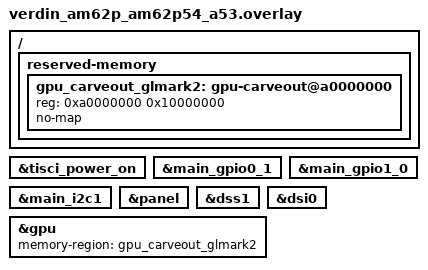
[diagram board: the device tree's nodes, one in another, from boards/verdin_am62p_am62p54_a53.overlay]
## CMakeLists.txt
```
# SPDX-License-Identifier: Apache-2.0
# SPDX-FileCopyrightText: 2026 Signal Slot, Inc.
# glmark2: glmark2-es2 (Linaro's OpenGL ES 2.0 benchmark) as a Zephyr image on
# the board layer, one source for the Verdin AM62P, the Verdin iMX8M Plus and
# the Raspberry Pi 4 (driver/docs/glmark2.md).
#
#   -DGLMARK2_SRC=<glmark2 checkout at GLMARK2_COMMIT>
#
# glmark2 is GPL-3.0-or-later (its libmatrix is MIT). It is never vendored or
# committed here: its sources are compiled by path from the fetched tree. The
# one file this port changes, libmatrix/util.cc (MIT), is copied into the
# build directory and patched there (patches/). Everything else of upstream
# is compiled unchanged, including CanvasGeneric, GLStateEGL, the glad
# loaders and the bundled libpng / zlib / libjpeg-turbo. Ours: the native
# state over the board layer and the run (src/main.cpp), the dlopen/dlsym
# shim over eglGetProcAddress and the data-file lookup (src/platform.c).
cmake_minimum_required(VERSION 3.20.0)

get_filename_component(PVR_REPO "${CMAKE_CURRENT_SOURCE_DIR}/../../.." ABSOLUTE)
include("${CMAKE_CURRENT_SOURCE_DIR}/../common/yakogl_dir.cmake")

# The STM32MP257F-DK's A35 takes the board layer's own app.conf (the Vivante
# driver, OP-TEE's watchdog, no hold), as gl_test, gc_fence and gc_clear do;
# boards/stm32mp257f_dk_stm32mp257fxx_a35.conf and .overlay add glmark2's own
# needs. Zephyr merges EXTRA_CONF_FILE after the board's .conf, so app.conf
# (HOLD_S=0) wins over prj.conf's.
if(NOT BOARD AND DEFINED ENV{BOARD})
  set(BOARD "$ENV{BOARD}")
endif()
if(BOARD MATCHES "^stm32mp257f_dk")
  set(EXTRA_CONF_FILE "${PVR_REPO}/zephyr/lib/board/stm32mp2/app.conf" ${EXTRA_CONF_FILE})
endif()

find_package(Zephyr REQUIRED HINTS $ENV{ZEPHYR_BASE})
project(glmark2_zephyr)

# ---------------------------------------------------------------------------
# The upstream tree, at the pinned commit and unmodified.
# ---------------------------------------------------------------------------
set(GLMARK2_COMMIT 22c527cb0556f3a1ac4445aaa52cc532760928d5)
set(GLMARK2_VERSION "2023.01") # meson.build project version at that commit
if(NOT GLMARK2_SRC AND DEFINED ENV{GLMARK2_SRC})
  set(GLMARK2_SRC "$ENV{GLMARK2_SRC}")
endif()
if(NOT GLMARK2_SRC OR NOT EXISTS "${GLMARK2_SRC}/src/default-benchmarks.h")
  message(FATAL_ERROR
    "glmark2: GLMARK2_SRC='${GLMARK2_SRC}' is not a glmark2 checkout. Fetch it:\n"
    "  git clone https://github.com/glmark2/glmark2 <dir> && git -C <dir> checkout ${GLMARK2_COMMIT}\n"
    "and pass -DGLMARK2_SRC=<dir>.")
endif()
execute_process(COMMAND git -C "${GLMARK2_SRC}" rev-parse HEAD
  OUTPUT_VARIABLE _gm_head OUTPUT_STRIP_TRAILING_WHITESPACE
  ERROR_QUIET RESULT_VARIABLE _gm_rc)
if(NOT _gm_rc EQUAL 0)
  set(_gm_head "unknown")
endif()
execute_process(COMMAND git -C "${GLMARK2_SRC}" status --porcelain --untracked-files=no
  OUTPUT_VARIABLE _gm_dirty OUTPUT_STRIP_TRAILING_WHITESPACE ERROR_QUIET)
if(NOT _gm_head STREQUAL GLMARK2_COMMIT OR NOT _gm_dirty STREQUAL "")
  # A score names the code that produced it: another commit, or a modified
  # tree, is not the pinned glmark2.
  message(FATAL_ERROR
    "glmark2: ${GLMARK2_SRC} is at '${_gm_head}' (local changes: '${_gm_dirty}'), "
    "not the pinned ${GLMARK2_COMMIT} without local changes.")
endif()
set(GM "${GLMARK2_SRC}/src")
set(GM_DATA "${GLMARK2_SRC}/data")
set(GM_BUILD "${CMAKE_CURRENT_BINARY_DIR}/glmark2")
message(STATUS "glmark2: upstream ${GLMARK2_COMMIT} (${GLMARK2_VERSION}) from ${GLMARK2_SRC}")

include("${CMAKE_CURRENT_SOURCE_DIR}/../common/sample.cmake")

# ---------------------------------------------------------------------------
# libmatrix/util.cc: copied and patched (Zephyr: the data files come from the
# image, the way upstream's ANDROID arm takes them from the APK's assets).
# ---------------------------------------------------------------------------
set(_util_patch "${CMAKE_CURRENT_SOURCE_DIR}/patches/libmatrix-util-zephyr.patch")
set(_util_cc "${GM_BUILD}/src/libmatrix/util.cc")
find_program(PATCH patch REQUIRED)
add_custom_command(OUTPUT "${_util_cc}"
  COMMAND ${CMAKE_COMMAND} -E make_directory "${GM_BUILD}/src/libmatrix"
  COMMAND ${CMAKE_COMMAND} -E copy "${GM}/libmatrix/util.cc" "${_util_cc}"
  COMMAND ${PATCH} --batch --forward -p1 -d "${GM_BUILD}" -i "${_util_patch}"
  DEPENDS "${GM}/libmatrix/util.cc" "${_util_patch}"
  COMMENT "glmark2: patching libmatrix/util.cc for Zephyr")

# ---------------------------------------------------------------------------
# The data files (data/shaders, data/models, data/textures), linked in as
# they are and decoded on the board by upstream's own readers. One .S with an
# .incbin per file and a table of {name, data, size}; the names are the paths
# glmark2 asks for under GLMARK_DATA_PATH ("/glmark2").
# ---------------------------------------------------------------------------
file(GLOB_RECURSE _gm_data_files RELATIVE "${GM_DATA}" CONFIGURE_DEPENDS
     "${GM_DATA}/shaders/*" "${GM_DATA}/models/*" "${GM_DATA}/textures/*")
list(SORT _gm_data_files)
set(_asm "/* generated by glmark2/CMakeLists.txt: the glmark2 data files */\n")
string(APPEND _asm "\t.section .rodata.glmark2_data, \"a\"\n")
set(_names "\t.section .rodata.glmark2_names, \"a\"\n")
set(_tab "\t.section .rodata.glmark2_table, \"a\"\n\t.balign 8\n")
string(APPEND _tab "\t.global glmark2_asset_table\nglmark2_asset_table:\n")
set(_i 0)
set(_bytes 0)
set(_deps)
foreach(f ${_gm_data_files})
  file(SIZE "${GM_DATA}/${f}" _sz)
  math(EXPR _bytes "${_bytes} + ${_sz}")
  list(APPEND _deps "${GM_DATA}/${f}")
  string(APPEND _asm "\t.balign 16\n.Ld${_i}:\n\t.incbin \"${GM_DATA}/${f}\"\n.Ld${_i}_end:\n")
  string(APPEND _names ".Ln${_i}:\n\t.asciz \"/glmark2/${f}\"\n")
  string(APPEND _tab "\t.quad .Ln${_i}, .Ld${_i}, .Ld${_i}_end - .Ld${_i}\n")
  math(EXPR _i "${_i} + 1")
endforeach()
string(APPEND _tab "\t.global glmark2_asset_table_count\n\t.balign 8\n")
string(APPEND _tab "glmark2_asset_table_count:\n\t.quad ${_i}\n")
set(_assets_s "${CMAKE_CURRENT_BINARY_DIR}/glmark2_assets.S")
file(CONFIGURE OUTPUT "${_assets_s}" CONTENT "${_asm}${_names}${_tab}")
set_source_files_properties("${_assets_s}" PROPERTIES OBJECT_DEPENDS "${_deps}")
message(STATUS "glmark2: ${_i} data files, ${_bytes} bytes linked in")

# ---------------------------------------------------------------------------
# Upstream's sources: src/meson.build's common_sources, the GLESv2 glad
# loader and the EGL state (the glmark2-es2 flavours), unchanged.
# ---------------------------------------------------------------------------
set(_gm_cxx
  benchmark-collection.cpp benchmark.cpp canvas-generic.cpp gl-headers.cpp
  gl-visual-config.cpp image-reader.cpp
  libmatrix/log.cc libmatrix/mat.cc libmatrix/program.cc libmatrix/shader-source.cc
  main-loop.cpp mesh.cpp model.cpp options.cpp results-file.cpp
  scene-buffer.cpp scene-build.cpp scene-bump.cpp scene-clear.cpp scene-conditionals.cpp
  scene.cpp scene-default-options.cpp scene-desktop.cpp scene-effect-2d.cpp
  scene-function.cpp scene-grid.cpp
  scene-ideas/a.cc scene-ideas.cpp scene-ideas/d.cc scene-ideas/e.cc scene-ideas/i.cc
  scene-ideas/lamp.cc scene-ideas/logo.cc scene-ideas/m.cc scene-ideas/n.cc
  scene-ideas/o.cc scene-ideas/s.cc scene-ideas/splines.cc scene-ideas/table.cc
  scene-ideas/t.cc
  scene-jellyfish.cpp scene-loop.cpp scene-pulsar.cpp scene-refract.cpp
  scene-shading.cpp scene-shadow.cpp
  scene-terrain/base-renderer.cpp scene-terrain/blur-renderer.cpp
  scene-terrain/copy-renderer.cpp scene-terrain.cpp scene-terrain/luminance-renderer.cpp
  scene-terrain/normal-from-height-renderer.cpp scene-terrain/overlay-renderer.cpp
  scene-terrain/renderer-chain.cpp scene-terrain/simplex-noise-renderer.cpp
  scene-terrain/terrain-renderer.cpp scene-terrain/texture-renderer.cpp
  scene-texture.cpp shared-library.cpp text-renderer.cpp texture.cpp
  gl-state-egl.cpp)
list(TRANSFORM _gm_cxx PREPEND "${GM}/")
set(_gm_glad "${GM}/glad/src/gles2.c" "${GM}/glad/src/egl.c")

# The bundled image libraries (src/{zlib,libpng,libjpeg-turbo}/meson.build).
set(_zlib adler32.c compress.c crc32.c deflate.c gzclose.c gzlib.c gzread.c gzwrite.c
  infback.c inffast.c inflate.c inftrees.c trees.c uncompr.c zutil.c)
list(TRANSFORM _zlib PREPEND "${GM}/zlib/")
set(_png png.c pngerror.c pnggccrd.c pngget.c pngmem.c pngpread.c pngread.c pngrio.c
  pngrtran.c pngrutil.c pngset.c pngtrans.c pngvcrd.c pngwio.c pngwrite.c pngwtran.c
  pngwutil.c)
list(TRANSFORM _png PREPEND "${GM}/libpng/")
set(_jpeg jcapimin.c jcapistd.c jccoefct.c jccolor.c jcdctmgr.c jchuff.c jcinit.c
  jcmainct.c jcmarker.c jcmaster.c jcomapi.c jcparam.c jcphuff.c jcprepct.c jcsample.c
  jdapimin.c jdapistd.c jdatadst.c jdatasrc.c jdcoefct.c jdcolor.c jddctmgr.c jdhuff.c
  jdinput.c jdmainct.c jdmarker.c jdmaster.c jdmerge.c jdphuff.c jdpostct.c jdsample.c
  jerror.c jfdctflt.c jfdctfst.c jfdctint.c jidctflt.c jidctfst.c jidctint.c jidctred.c
  jmemmgr.c jmemnobs.c jquant1.c jquant2.c jsimd_none.c jutils.c)
list(TRANSFORM _jpeg PREPEND "${GM}/libjpeg-turbo/")

# Upstream's code is built in static libraries of its own, with upstream's
# warnings (-w: not our warning set), and with the kernel's flags and headers
# through zephyr_interface: Zephyr's way for libraries of an application
# (zephyr_library() is for modules). The app links them; the linker pulls in
# what main.cpp references (SceneCollection registers every scene).
foreach(lib zlib png jpeg)
  add_library(glmark2_${lib} STATIC ${_${lib}})
  target_include_directories(glmark2_${lib} PRIVATE
    "${GM}/zlib" "${GM}/libpng" "${GM}/libjpeg-turbo")
  target_compile_options(glmark2_${lib} PRIVATE -w)
  target_link_libraries(glmark2_${lib} PUBLIC zephyr_interface)
  # kernel.h includes generated headers (heap_constants.h, ...)
  add_dependencies(glmark2_${lib} zephyr_generated_headers)
endforeach()
# zlib's gz* file functions use read/write/lseek/close: zlib's own configure
# defines Z_HAVE_UNISTD_H on a POSIX system.
target_compile_definitions(glmark2_zlib PRIVATE Z_HAVE_UNISTD_H)
target_compile_definitions(glmark2_png PRIVATE Z_HAVE_UNISTD_H)

add_library(glmark2_upstream STATIC ${_gm_cxx} ${_gm_glad} "${_util_cc}")
# YakoGL's include/ first: glad's EGL header takes <EGL/eglplatform.h> and
# <KHR/khrplatform.h> from there, so EGLNativeWindowType is YakoGL's
# struct gles_native_window * (glad's own eglplatform.h has no Zephyr arm).
# include/ holds the getopt.h, unistd.h and dlfcn.h glmark2 expects of a
# POSIX system (each says why).
target_include_directories(glmark2_upstream BEFORE PRIVATE
  "${YAKOGL_DIR}/include"
  "${GM}/glad/include" "${GM}" "${GM}/libmatrix" "${GM}/scene-ideas" "${GM}/scene-terrain"
  "${GM}/libpng" "${GM}/zlib" "${GM}/libjpeg-turbo"
  "${CMAKE_CURRENT_SOURCE_DIR}/include")
# _GNU_SOURCE: what g++ predefines on Linux, where glmark2 is built. Zephyr's
# POSIX layer sets _POSIX_C_SOURCE=200809L, which alone hides picolibc's XSI
# and BSD names (M_PI, used by the scenes).
target_compile_definitions(glmark2_upstream PRIVATE _GNU_SOURCE
  GLMARK2_USE_GLESv2 GLMARK2_USE_EGL USE_EXCEPTIONS
  GLMARK_VERSION="${GLMARK2_VERSION}" GLMARK_DATA_PATH="/glmark2"
  GLMARK2_EXECUTABLE="glmark2-es2")
target_compile_options(glmark2_upstream PRIVATE -w)
target_link_libraries(glmark2_upstream PUBLIC zephyr_interface
  glmark2_png glmark2_jpeg glmark2_zlib)
add_dependencies(glmark2_upstream zephyr_generated_headers)

# ---------------------------------------------------------------------------
# Ours.
# ---------------------------------------------------------------------------
target_sources(app PRIVATE src/main.cpp src/platform.c "${_assets_s}")
target_include_directories(app BEFORE PRIVATE
  "${YAKOGL_DIR}/include" "${CMAKE_CURRENT_SOURCE_DIR}/include"
  "${GM}/glad/include" "${GM}" "${GM}/libmatrix")
# The V3D OSAL's job times (zephyr_v3d.h), for the frame-cost line.
target_include_directories(app PRIVATE "${YAKOGL_DIR}/src/osal")
# The PowerVR backend's options (pvr_backend.h), for
# CONFIG_GLMARK2_PVR_ONE_KICK_IN_FLIGHT.
target_include_directories(app PRIVATE "${YAKOGL_DIR}/src/pvr")
target_compile_definitions(app PRIVATE
  GLMARK2_USE_GLESv2 GLMARK2_USE_EGL USE_EXCEPTIONS
  GLMARK2_COMMIT="${GLMARK2_COMMIT}" GLMARK_VERSION="${GLMARK2_VERSION}")
target_link_libraries(app PRIVATE glmark2_upstream)
```

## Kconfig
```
# SPDX-License-Identifier: Apache-2.0
# SPDX-FileCopyrightText: 2026 Signal Slot, Inc.
# What the glmark2 image runs (driver/docs/glmark2.md).

menu "glmark2"

config GLMARK2_SIZE
	string "Window size, WxH"
	default "800x600"
	help
	  The size of the board window, handed to glmark2 as --size. 800x600
	  is glmark2's own default (options.cpp:37) and the size of most
	  published glmark2-es2 runs on these boards; it fits all three panels
	  (1024x600, 1280x800, 1920x720). A window larger than the board can
	  give is refused by board_window() at the start of the run.

config GLMARK2_ARGS
	string "More glmark2 arguments, separated by spaces"
	default ""
	help
	  Appended after --size, e.g. "--off-screen" or
	  "-b build:use-vbo=true -b texture". Empty: the default benchmark
	  list (default-benchmarks.h, 33 scenes of 10 s each). --size and
	  --fullscreen here are refused (the window is sized from
	  GLMARK2_SIZE); --results-file needs a file system and is refused.

config GLMARK2_PVR_ONE_KICK_IN_FLIGHT
	bool "PowerVR: one kick in flight (measurement)"
	depends on YAKOGL_DRV_GPU_PVR
	help
	  Sets the PowerVR backend's PVR_BACKEND_OPT_ONE_IN_FLIGHT before the
	  first scene: each swap waits for its own frame's kick, not only for
	  the ones before it, so every kick starts on an idle GPU. With
	  CONFIG_YAKOGL_DRV_GPU_PVR_KICK_TIMES the kick line then shows the alone
	  cost of a frame's kick
	  (docs/notes/pvr-fence-wait.md, "The next
	  experiment"). A measurement knob: off for a score.

config GLMARK2_GC_TILED_RT
	bool "GC7000: tiled render targets and early depth (measurement)"
	depends on YAKOGL_DRV_GPU_VIVANTE
	select YAKOGL_TEST_KNOBS
	help
	  Calls gc_debug_set_tiled_rt(1) before the first scene: the Vivante
	  backend's tiled shadow targets, resolved by the RS in the same stream,
	  and early depth into them (docs/notes/gc-tiled-wire.md). The knob
	  exists only with CONFIG_YAKOGL_TEST_KNOBS, which this selects.
	  A measurement knob: off for a score.

config GLMARK2_FRAME_DUMP
	bool "Print each scene's last frame as text on the console"
	help
	  After a scene's last frame is read back for the picture value, prints
	  the whole window as "glmark2-fb:" lines (one base64 RGB888 row per
	  line, with the row number and a crc16, then a crc32 of the frame):
	  800x600 is about 1.9 MB, minutes of UART. tools/cts/glmark2-fb.py
	  turns the console log into a PNG (driver/docs/glmark2.md, "The frame
	  dump"). For a picture of one scene (GLMARK2_ARGS names it); off in every
	  gate and common-set image.

endmenu

source "Kconfig.zephyr"
```

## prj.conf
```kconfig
# SPDX-License-Identifier: Apache-2.0
# SPDX-FileCopyrightText: 2026 Signal Slot, Inc.
# The glmark2 image: the same configuration on every board. What a board
# needs beyond it (its GPU driver, display path, memory) is in boards/.
CONFIG_YAKOGL=y
CONFIG_YAKOGL_BOARD=y
# glmark2 builds its shaders at run time (options substituted into the
# sources): the in-process compiler.
CONFIG_YAKOGL_SHADERC_ONLINE=y

CONFIG_PRINTK=y
CONFIG_LOG=y
CONFIG_LOG_MODE_MINIMAL=y
CONFIG_CACHE_MANAGEMENT=y
CONFIG_FPU=y

# glmark2 is C++17 with exceptions (-DUSE_EXCEPTIONS), std::map/std::string
# everywhere, std::filesystem::path and iostreams: the full libstdc++, as
# dEQP has (deqp/prj.conf, deqp/README.md).
CONFIG_CPP=y
CONFIG_STD_CPP17=y
CONFIG_REQUIRES_FULL_LIBCPP=y
CONFIG_CPP_EXCEPTIONS=y
CONFIG_CPP_RTTI=y
# The SDK's libstdc++.a is built with a 64-bit `long` int64_t
# (deqp/README.md, "Configuration that matters").
CONFIG_ENFORCE_ZEPHYR_STDINT=n
# getopt_long for Options::parse_args; std::chrono::steady_clock for the
# frame times (clock_gettime).
CONFIG_POSIX_API=y
CONFIG_POSIX_C_LIB_EXT=y
CONFIG_GETOPT_LONG=y

# The online compiler needs 256 KiB of stack (examples/triangle/prj.conf); the
# scenes' model loaders recurse little. dEQP's 1 MiB, measured enough there.
CONFIG_MAIN_STACK_SIZE=1048576
CONFIG_STACK_SENTINEL=y
# The heap: decoded textures (largest 1024x1024x3, 3 MiB, plus libpng's row
# buffers), the parsed models (bunny.obj 2.4 MB of text) and the meshes.
# 96 MiB; the high-water mark is not measured yet.
CONFIG_COMMON_LIBC_MALLOC=y
CONFIG_COMMON_LIBC_MALLOC_ARENA_SIZE=100663296

# The run: 33 scenes of 10 s plus their set-up (shader compiles at about
# 0.2 s each on the A53, deqp/README.md) is about 6-7 minutes; the
# watchdog is fed until 15 minutes after boot at most, and every main-loop
# step says it is alive (NativeStateBoard::should_quit).
CONFIG_YAKOGL_BOARD_LIFETIME_S=900
CONFIG_YAKOGL_BOARD_HOLD_S=20
```

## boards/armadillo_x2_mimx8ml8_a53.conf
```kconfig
# SPDX-License-Identifier: Apache-2.0
# SPDX-FileCopyrightText: 2026 Signal Slot, Inc.
# Armadillo-X2 (i.MX8M Plus, same SoC and GC7000UL as the Verdin): what the
# board needs beyond prj.conf. The image is kexec'd out of Armadillo Base OS
# by tools/board.sh x2 run (kexec-dev, a development run); the record is read
# from SNVS LPGPR1..3 (three words).
#
# Build, one scene (CONFIG_GLMARK2_ARGS="-b terrain" selects it; any
# "-b <scene>" works, empty runs the default list):
#
#   export $(tools/cts/deps-env.sh imx8mp)
#   . "$ZEPHYR_VENV/bin/activate"
#   export ZEPHYR_BASE=$ZEPHYR_WS/zephyr
#   west build -p always -d <dir> -b armadillo_x2/mimx8ml8/a53 \
#       driver/samples/zephyr/glmark2 -- \
#       "-DZEPHYR_MODULES=$(tools/cts/zephyr-modules.sh $ZEPHYR_WS)" \
#       -DGLMARK2_SRC=$GLMARK2_SRC '-DCONFIG_GLMARK2_ARGS="-b terrain"'
#
# Check it; the run itself is a board session, not part of the build:
#   strings <dir>/zephyr/zephyr.bin | grep 'gc_wdog_arm: armed'
#   tools/board.sh --dry-run x2 run <dir>/zephyr/zephyr.bin <logdir>
CONFIG_YAKOGL_DRV_GPU_VIVANTE=y
CONFIG_YAKOGL_GPU_VIVANTE=y
# Board support of the GC images: the GIC EOI fix, the interrupt guard, the
# watchdog, the SNVS result record (gl_test's boards/imx8mp.conf has the same).
CONFIG_YAKOGL_GC_BOARD=y
# FPU sharing off on purpose, as the Verdin's.
CONFIG_FPU_SHARING=n
# The console is UART2, wired to the host: print there, not into the picture.
CONFIG_UART_CONSOLE=y
CONFIG_GC_COMMON_PANEL_CONSOLE=n
# tools/board.sh x2 refuses an image that does not print "gc_wdog_arm: armed".
CONFIG_GC_BOARD_WDOG_SELF_ARM=y
CONFIG_GPIO=y
CONFIG_I2C=y
CONFIG_PINCTRL=y
CONFIG_YAKOGL_DRV_DISPLAY_IMX8MP=y
CONFIG_PM_CPU_OPS=y
CONFIG_PM_CPU_OPS_PSCI=y
# Address space for the 240 MiB GPU carve-out of the overlay: the image with
# its 96 MiB heap plus that mapping is past the default 256 MiB of VM from
# 0x60000000 (the Verdin's conf has the same line, issue #814).
CONFIG_KERNEL_VM_SIZE=0x20000000
```

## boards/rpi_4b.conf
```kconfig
# SPDX-License-Identifier: Apache-2.0
# SPDX-FileCopyrightText: 2026 Signal Slot, Inc.
# Raspberry Pi 4: what the board needs beyond prj.conf, as slint/boards has
# it. Not built yet (driver/docs/glmark2.md).
CONFIG_YAKOGL_GPU_V3D=y
# 96 MiB of GPU memory (a static of the image; see rpi_4b.overlay): refract
# peaks at about 56.2 MB (its 1600x1200 copy, 7,684,096 B, did not fit the
# former 48 MiB: tools/cts/RESULTS.md, "out of GPU memory") and terrain needs
# over 30.5 MB, +33% since its 800x600 textures have NPOT mip chains. The
# carve-out and the 512 KiB page table sit inside the GPU's 512 MiB VA space
# (src/osal/zephyr_v3d.c, VA_SPACE), so 96 MiB has room.
CONFIG_YAKOGL_V3D_CARVEOUT_BYTES=100663296
# glmark2 refract's 1600x1200 RGBA8 colour render target tiles to 11,001,856 B
# with its mip chain: over the 8 MiB default, so one of its draws was refused
# (3 x GL error 0x505). Measured on the host harness at this carve-out: 24 MiB
# keeps that copy and the 7,684,096 B depth copy at once (tiled high-water
# 19,742,720 B; refract peak 69,093,376 of the 96 MiB carve-out, below the
# 70,146,048 of 16 MiB, which evicts the depth copy every frame; both run
# refract at 23 FPS):
# tools/hostharness/glmark2/FINDINGS-refract-budget.md sections 3.2-3.4.
CONFIG_YAKOGL_V3D_TILED_COPIES_BYTES=25165824
# The texture formatting unit: a colour render target the scene samples is
# stored by the tile list into its render image, and its glGenerateMipmap
# (refract's and terrain's, every frame) is one TFU job in that image instead
# of the CPU's box filter over 7.68 MB of non-cacheable storage
# (docs/online-shaderc/v3d-backend.md, "Render targets sampled from their
# render image"); the OSAL runs TFU jobs only with this option. Kept copies
# of 64 KiB or more are the TFU's too (case 140: 2.2 ms against 145 ms for a
# 1920x720 image). The first board run of the TFU's mipmap job is this
# image's.
CONFIG_YAKOGL_V3D_TFU=y
CONFIG_FPU_SHARING=y
# Address space: the image's 288 MiB (rpi_4b.overlay), the carve-out's
# non-cacheable alias (96 MiB), the window's alias, the framebuffer and the
# device blocks: more than slint's 256 MiB. deqp's pair, which runs on
# this board with a 256 MiB image (deqp/boards/rpi_4b.conf).
# The alias is 4 KiB pages, a table per 2 MiB: 48 for it, so 192 tables.
CONFIG_MAX_XLAT_TABLES=192
CONFIG_KERNEL_VM_SIZE=0x20000000
```

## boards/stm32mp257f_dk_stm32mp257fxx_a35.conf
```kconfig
# SPDX-License-Identifier: Apache-2.0
# SPDX-FileCopyrightText: 2026 Signal Slot, Inc.
# STM32MP257F-DK, Cortex-A35 (Vivante GCNanoUltra31, 0x8000/0x6205): what the
# board needs beyond prj.conf. The board layer's app.conf (the Vivante driver,
# OP-TEE's watchdog, no hold) is added by CMakeLists.txt, as in gl_test
# (boards/stm32mp257f_dk_stm32mp257fxx_a35.conf there, commit fb94dafe). Build
# only for now: the DK's board layer has no window or screen yet
# (board_stm32mp2.c: board_window() refuses), so the image links but a run
# ends at the first scene; the display is the DK's P8.
CONFIG_YAKOGL_BOARD=y
# The layer resets the board this long after boot whatever the run does: the
# default list is 33 scenes of 10 s plus set-up (prj.conf: about 6-7 minutes);
# tools/board-stm32mp2.sh's RUN_BOUND (120 s) has to be raised for it.
CONFIG_YAKOGL_STM32MP2_LIFETIME_S=900
# Address space for the 240 MiB GPU carve-out of the overlay: the image with
# its 96 MiB heap plus that mapping (gc_render.c, k_mem_map_phys_bare) is past
# the default 256 MiB of VM from 0xa0000000 (the Verdin iMX8M Plus' conf has
# the same line, issue #814).
CONFIG_KERNEL_VM_SIZE=0x20000000
```

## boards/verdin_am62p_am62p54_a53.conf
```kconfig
# SPDX-License-Identifier: Apache-2.0
# SPDX-FileCopyrightText: 2026 Signal Slot, Inc.
# Verdin AM62P: what the board needs beyond prj.conf, as slint/boards has it.
CONFIG_YAKOGL_DRV_GPU_PVR=y
CONFIG_FPU_SHARING=y
# A window up to 1920x1080 (8100 KiB), for an off-screen run at the size of
# the --fullscreen runs; the default 800x600 needs 1875.
CONFIG_YAKOGL_BOARD_WINDOW_MAX_KB=8100

# Init order: mailbox 40 -> TISCI 45 -> TISCI power-on 46 -> GPIO 47 ->
# I2C 50 -> DSI 70 -> DSS 80 -> GPU 90 -> panel bridge 95.
CONFIG_MBOX=y
CONFIG_MBOX_TI_SECURE_PROXY=y
CONFIG_TISCI=y
CONFIG_TISCI_INIT_PRIORITY=45
CONFIG_GPIO_INIT_PRIORITY=47
CONFIG_YAKOGL_DRV_SN65DSI8X_SELF_START_INIT_PRIORITY=95

# Address space for the 256 MiB GPU carve-out of the overlay (as the dEQP
# image has it): at the default the carve-out's mapping fails at boot
# ("insufficient virtual address space").
CONFIG_MAX_XLAT_TABLES=128
CONFIG_KERNEL_VM_SIZE=0x20000000
```

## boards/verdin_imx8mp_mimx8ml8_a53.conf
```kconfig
# SPDX-License-Identifier: Apache-2.0
# SPDX-FileCopyrightText: 2026 Signal Slot, Inc.
# Verdin iMX8M Plus (Mallow): what the board needs beyond prj.conf, as
# slint/boards has it. Not built yet (driver/docs/glmark2.md).
CONFIG_YAKOGL_DRV_GPU_VIVANTE=y
CONFIG_YAKOGL_GPU_VIVANTE=y
# FPU sharing off on purpose (slint/boards/verdin_imx8mp_mimx8ml8_a53.conf).
CONFIG_FPU_SHARING=n
# No UART on the Mallow: the console is the board layer's panel console.
CONFIG_UART_CONSOLE=n
CONFIG_GPIO=y
CONFIG_I2C=y
CONFIG_PINCTRL=y
CONFIG_YAKOGL_DRV_DISPLAY_IMX8MP=y
CONFIG_PM_CPU_OPS=y
CONFIG_PM_CPU_OPS_PSCI=y
# Address space for the 240 MiB GPU carve-out of the overlay:
# the image with its 96 MiB heap plus that mapping (gc_render.c,
# k_mem_map_phys_bare) is past the default 256 MiB of VM from 0x60000000,
# where the mapping fails at boot; 512 MiB, as the dEQP image of this board
# and the AM62P's glmark2 image have it.
CONFIG_KERNEL_VM_SIZE=0x20000000
```

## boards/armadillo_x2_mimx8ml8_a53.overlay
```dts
/* SPDX-License-Identifier: Apache-2.0 */
/* SPDX-FileCopyrightText: 2026 Signal Slot, Inc. */
/*
 * Armadillo-X2 (board definition: driver/boards/atmark/armadillo_x2). Two
 * changes for glmark2, neither in the board's own files.
 *
 * GPU carve-out: 240 MiB instead of the board's 128 MiB, as the Verdin's
 * glmark2 overlay has (issue #814: every GC7000 allocation of all the scenes
 * of a run comes from this one pool, and a refused allocation is a GL error).
 * It stays inside the 256 MiB at 0x80000000 that the board's map gives
 * galcore (gcContMem, no-map for Linux), ends at 0x8f000000 below Linux's
 * 0x90000000, and is 4 MiB aligned below 4 GiB as the GC's MMU needs. 240 MiB
 * is 60 of the 64 slave tables (gc_internal.h GC_STLB_COUNT). The image itself
 * stays in a53_ddr_section, 256 MiB at 0x60000000, the window tools/board.sh
 * x2 checks.
 *
 * Display: the board's devicetree expects the 1920x1200 that Linux ran on the
 * monitor; the HDMI sink now is a 1920x1080 capture device, and the adopt
 * driver refuses a LCDIF that runs another mode ("the LCDIF runs 1920x1080,
 * the devicetree expects 1920x1200"). It adopts the running mode and only
 * checks it against these two properties, so they say what runs.
 */
&gpu_carveout {
	reg = <0x80000000 0x0f000000>;
};

&display0 {
	hactive = <1920>;
	vactive = <1080>;
};
```

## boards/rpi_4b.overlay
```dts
/* SPDX-License-Identifier: Apache-2.0 */
/* SPDX-FileCopyrightText: 2026 Signal Slot, Inc. */
/*
 * The board's sram0 is 512 KiB at 0x200000 (dts/arm64/broadcom/bcm2711.dtsi).
 * This image carries the V3D's 96 MiB carve-out, the compiler's 2 MiB
 * scratch, the 96 MiB C heap (prj.conf), the window and glmark2's ~9.4 MB
 * of data files, so it gets 288 MiB from 0x200000, to 0x12200000 (an
 * estimate: the 224 MiB image of the 48 MiB carve-out took 194,192 KiB,
 * driver/docs/glmark2.md; +48 MiB is about 242 MiB). DRAM starts at 0 on the
 * Pi 4 and the firmware keeps its own memory at the top of the first GiB (the
 * framebuffer is at 0x3c100000), so this is ARM memory on every Pi 4.
 */
#include "../../common/rpi_4b_sram.dtsi"

&sram0 {
	reg = <0x200000 0x12000000>;
};
```

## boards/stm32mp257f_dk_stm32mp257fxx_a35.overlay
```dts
/* SPDX-License-Identifier: Apache-2.0 */
/* SPDX-FileCopyrightText: 2026 Signal Slot, Inc. */
/* The STM32MP257F-DK's A35: the board layer's GPU node (clock rate), as
 * gl_test, gc_fence and gc_clear take it, and a larger carve-out than the
 * board's. */
#include "../../../../zephyr/lib/board/stm32mp2/app.overlay"

/* A 240 MiB GPU carve-out instead of the board's 64 MiB gpu-reserved area at
 * 0xfa800000 (driver/boards/st/stm32mp257f_dk), as the Verdin iMX8M Plus'
 * glmark2 image takes (issue #814): every GC allocation of the scenes comes
 * from this one pool, frees are held until their kick completes, and one
 * scene's peak (terrain) is 51 MB on the host, more than 64 MiB holds with
 * the scenes running one after another. ST's area cannot grow: System RAM
 * ends at 0xfa7fffff, and U-Boot relocates just below that.
 *
 * Where: 0xb0000000, just above the image's 256 MiB (zephyr,sram at
 * 0xa0000000, the link address) and far below U-Boot, which relocates to the
 * top of usable RAM. It is System RAM in ST's Linux (0x84000000-0xfa7fffff),
 * not a reserved area, so unlike gpu-reserved it is not known to be open to
 * the GPU's bus master: the first run on the DK confirms it (gc_fence's
 * carve-out check). Below 4 GiB and 4 MiB aligned, as the GC's MMU needs
 * (mmu.rs); 240 MiB is 60 of the 64 slave tables the carve-out's head holds
 * (gc_internal.h GC_STLB_COUNT). */
/ {
	reserved-memory {
		gpu_carveout_glmark2: gpu-carveout@b0000000 {
			reg = <0xb0000000 0x0f000000>;
			no-map;
		};
	};
};

&gpu {
	memory-region = <&gpu_carveout_glmark2>;
};
```

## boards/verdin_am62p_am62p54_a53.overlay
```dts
/* SPDX-License-Identifier: Apache-2.0 */
/* SPDX-FileCopyrightText: 2026 Signal Slot, Inc. */
/*
 * Toradex Verdin AM62P (board definition). The board DTS has the GPU
 * node with its 64 MiB carveout and the display path wired but disabled
 * (the R5F owns the display in the platform). This stand-alone
 * application drives the panel itself, so it enables DSS1, DSI, the bridge
 * on I2C1, the GPIO banks and the TISCI power-on list.
 */

&tisci_power_on {
	status = "okay";
};

&main_gpio0_1 {
	status = "okay";
};

&main_gpio1_0 {
	status = "okay";
};

&main_i2c1 {
	status = "okay";
};

&panel {
	status = "okay";
};

&dss1 {
	status = "okay";
};

&dsi0 {
	status = "okay";
};

/* A 256 MiB GPU carve-out instead of the board's 64 MiB one, as the dEQP
 * image takes (driver/samples/zephyr/deqp/boards/, run from U-Boot on
 * 2026-10-12 with 0 resets). At 64 MiB about 36 MiB are taken whatever the
 * scene (firmware, parameter buffer, freelists, HWRT sets;
 * docs/notes/pvr-render-pool.md), so terrain's 5.6 MB
 * NPOT mip chain and shadow's 22 MB depth chain cannot fit and refract's
 * target allocations are refused. The board's 64 MiB region
 * stays reserved but unused. */
/ {
	reserved-memory {
		gpu_carveout_glmark2: gpu-carveout@a0000000 {
			reg = <0xa0000000 0x10000000>;
			no-map;
		};
	};
};

&gpu {
	memory-region = <&gpu_carveout_glmark2>;
};
```

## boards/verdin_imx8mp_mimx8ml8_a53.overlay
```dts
/* SPDX-License-Identifier: Apache-2.0 */
/* SPDX-FileCopyrightText: 2026 Signal Slot, Inc. */
/* The display chain of the Verdin iMX8M Plus on a Mallow carrier. */
#include "../../common/verdin_imx8mp_display.dtsi"

/* A 240 MiB GPU carve-out instead of the board's 64 MiB one.
 * Every GC7000 allocation comes from this one pool (src/osal/zephyr_gc.c),
 * and so do the board layer's 800x600 window and its 1280x800 screen copy
 * (5.7 MiB). At 64 MiB the GC's own peak in terrain is 51 MB on the host
 * (tools/hostharness/glmark2, one scene per process, frees returned at
 * once); on the board the frees are held until their kick completes and the
 * scenes run one after another in one pool, and a refused allocation is a
 * GL error (the record's "GL errors raised 15 or more" on every common set).
 * The AM62P's image took the same step for the same scenes (its overlay,
 * 256 MiB: 2573 GL errors to 0).
 *
 * Where: 0x70000000, above the image's 256 MiB at 0x60000000 and below the
 * M7's reserved 0x80000000 (the board's Linux /proc/iomem: System RAM from
 * 0x55500000 to 0x7fffffff; nothing runs from it while this image does).
 * Below 4 GiB and 4 MiB-aligned, as the GC's MMU needs (mmu.rs: the
 * carve-out is identity-mapped, one slave table per 4 MiB).
 * How much: 240 MiB, 60 of the 64 slave tables the carve-out's head holds
 * (gc_internal.h GC_STLB_COUNT, 256 MiB of VA); the other four are for
 * gc_render_map_phys's imports. tools/hostharness/glmark2/run.sh reads this
 * node, so the host run models the same memory. */
/ {
	reserved-memory {
		gpu_carveout_glmark2: gpu-carveout@70000000 {
			reg = <0x70000000 0x0f000000>;
			no-map;
		};
	};
};

&gpu3d {
	memory-region = <&gpu_carveout_glmark2>;
};
```

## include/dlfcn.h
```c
/* SPDX-License-Identifier: Apache-2.0 */
/* SPDX-FileCopyrightText: 2026 Signal Slot, Inc. */
/*
 * dlfcn.h for the glmark2 image: glmark2's SharedLibrary (shared-library.cpp)
 * opens libEGL / libGLESv2 with dlopen and takes every entry point with
 * dlsym. In the image YakoGL is linked in, so "opening" a library always
 * succeeds and dlsym is eglGetProcAddress, which answers for every EGL and GL
 * entry point YakoGL has (src/gl/egl.rs, the PROCS table). src/platform.c.
 */
#ifndef GLMARK2_DLFCN_H
#define GLMARK2_DLFCN_H

#ifdef __cplusplus
extern "C" {
#endif

#define RTLD_LAZY     0x0001
#define RTLD_NOW      0x0002
#define RTLD_GLOBAL   0x0100
#define RTLD_LOCAL    0x0000
#define RTLD_NODELETE 0x1000

void *dlopen(const char *filename, int flags);
void *dlsym(void *handle, const char *symbol);
int dlclose(void *handle);
char *dlerror(void);

#ifdef __cplusplus
}
#endif

#endif /* GLMARK2_DLFCN_H */
```

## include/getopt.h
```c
/* SPDX-License-Identifier: Apache-2.0 */
/* SPDX-FileCopyrightText: 2026 Signal Slot, Inc. */
/*
 * getopt.h for glmark2's options.cpp: Zephyr's getopt.h
 * (subsys/portability/posix/c_lib_ext/getopt) declares getopt_long but not
 * optarg/optind, which POSIX puts in <unistd.h> and glibc's getopt.h also
 * declares. options.cpp includes only <getopt.h>, as on glibc.
 */
#ifndef GLMARK2_GETOPT_H
#define GLMARK2_GETOPT_H

#include_next <getopt.h>
#include <unistd.h>

#endif /* GLMARK2_GETOPT_H */
```

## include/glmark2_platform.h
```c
/* SPDX-License-Identifier: Apache-2.0 */
/* SPDX-FileCopyrightText: 2026 Signal Slot, Inc. */
/*
 * glmark2_platform.h -- what glmark2's patched libmatrix/util.cc
 * (patches/libmatrix-util-zephyr.patch) asks of the image: the data files
 * linked in by CMakeLists.txt (glmark2_assets.S) and the CPU count.
 * Implemented in src/platform.c.
 */
#ifndef GLMARK2_PLATFORM_H
#define GLMARK2_PLATFORM_H

#include <stddef.h>

#ifdef __cplusplus
extern "C" {
#endif

/* The data file at `path` (e.g. "/glmark2/textures/crate-base.png"):
 * 0 and *data, *size; -1 when the image holds no such file. */
int glmark2_asset_find(const char *path, const void **data, size_t *size);

/* The number of linked-in files, and the path of file i (< count). */
size_t glmark2_asset_count(void);
const char *glmark2_asset_name(size_t i);

/* The CPUs Zephyr runs on (arch_num_cpus()). */
unsigned int glmark2_num_cpus(void);

#ifdef __cplusplus
}
#endif

#endif /* GLMARK2_PLATFORM_H */
```

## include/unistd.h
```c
/* SPDX-License-Identifier: Apache-2.0 */
/* SPDX-FileCopyrightText: 2026 Signal Slot, Inc. */
/*
 * unistd.h for glmark2: Zephyr's <unistd.h> plus isatty(), which Zephyr does
 * not have with picolibc (only lib/libc/newlib/libc-hooks.c defines one).
 * glmark2's libmatrix/log.cc asks isatty(fileno(stdout)) to decide whether to
 * colour its lines; src/platform.c answers "not a terminal" (the console is a
 * UART log, read by tools, not a terminal).
 */
#ifndef GLMARK2_UNISTD_H
#define GLMARK2_UNISTD_H

#include_next <unistd.h>

#ifdef __cplusplus
extern "C" {
#endif

int isatty(int fd);

#ifdef __cplusplus
}
#endif

#endif /* GLMARK2_UNISTD_H */
```

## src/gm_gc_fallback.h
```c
/* SPDX-License-Identifier: Apache-2.0 */
/* SPDX-FileCopyrightText: 2026 Signal Slot, Inc. */
/*
 * gm_gc_fallback.h: the GC7000 back end's fallback and wait counters, the
 * source of PERF page 4 (gm_perf_page.h). The library provides the strong
 * definition of yakogl_gc_fallback_stats (item fb-counters); the sample
 * defines a __weak one returning -ENOTSUP, so an image built before the
 * library counters exist reports "not available" (page 4 = 0xffff in every
 * value) and cannot be mistaken for zero.
 *
 * The contract: every field is a cumulative count since boot, never reset,
 * 64 bits wide (no wrap to handle). The page takes the difference between
 * the scene's first frame and the end of its last.
 */
#ifndef GM_GC_FALLBACK_H
#define GM_GC_FALLBACK_H

#include <stdint.h>

#ifdef __cplusplus
extern "C" {
#endif

struct yakogl_gc_fallback_stats {
	/* glGenerateMipmap chains the GPU drew (once per call, however many
	 * levels the chain has) */
	uint64_t gpu_mip_chains;
	/* glGenerateMipmap calls that took the CPU filter instead */
	uint64_t cpu_mip_calls;
	/* times the CPU waited for the GPU outside the swap (the depth
	 * resolve's finish(), a tiled copy of a rendered texture, a readback
	 * of a render target; the swap's own wait is page 1) */
	uint64_t gpu_waits;
	/* bytes the CPU read or wrote in passes over the GPU carve-out
	 * (non-cacheable memory: tiled copies, CPU mipmaps, depth resolves) */
	uint64_t carveout_cpu_bytes;
};

/* Fills *out. 0 on success; -ENOTSUP when this build keeps no such counters
 * (the sample's weak definition); another negative errno on failure, which
 * the page treats like -ENOTSUP. */
int yakogl_gc_fallback_stats(struct yakogl_gc_fallback_stats *out);

#ifdef __cplusplus
}
#endif

#endif /* GM_GC_FALLBACK_H */
```

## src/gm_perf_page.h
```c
/* SPDX-License-Identifier: Apache-2.0 */
/* SPDX-FileCopyrightText: 2026 Signal Slot, Inc. */
/*
 * gm_perf_page.h: the glmark2 image's frame-breakdown record, packed
 * (docs/notes/imx8mp-frame-floor.md, "The frame-breakdown record"). Pure C,
 * no Zephyr: main.cpp gathers a scene's totals into struct gm_perf_scene,
 * and the functions here turn them into one page of a kind PERF record.
 * host/perf_page_test.c packs known pages into known words on the host.
 *
 * The record: w0 = YK_RECORD_MAGIC | YK_RECORD_KIND_PERF << 8 | page
 * (experiment 0, so the tag is the page: 0x594b0c00 | page); w1..w3 = six
 * 16-bit values v0..v5, v0 in w1's low half (w1 = v1 << 16 | v0,
 * w2 = v3 << 16 | v2, w3 = v5 << 16 | v4). yakogl-tools record decodes it
 * as "experiment 0 page p: v0 v1 v2 v3 v4 v5". Every value saturates at
 * 0xffff. A mean whose count is 0 is 0. Means are rounded down.
 *
 *   page 0, the frame (us per frame, over the scene's frames):
 *     v0 frames, v1 frame (t2 - t0), v2 gl (t1 - t0), v3 swap, v4 show,
 *     v5 frame to frame (t0 to the next t0, over the intervals)
 *   page 1, the swap (per frame, or per 100 frames):
 *     v0 wait us, v1 waits per 100 frames, v2 gc_render_wait sleeps per 100
 *     frames, v3 GPU busy us, v4 kicks per 100 frames, v5 submit us
 *   page 2, the display (counts of frame-to-frame intervals):
 *     v0 under 1.5 T, v1 in [1.5 T, 2.5 T), v2 at 2.5 T or more, v3 T in us
 *     (0: not measured, and v0..v2 are 0), v4 frames whose present (swap +
 *     show) took 1000 us or more, v5 the kernel tick rate
 *   page 3, the GPU (per frame-to-frame interval):
 *     v0 HI total kcycles, v1 HI idle kcycles, v2 KiB read, v3 KiB written,
 *     v4 core MHz (total cycles / frame-to-frame us), v5 0
 *   page 4, the back end's fallbacks (gm_gc_fallback.h; v4 = v5 = 0, so
 *     w3 = 0, and only w1 and w2 are stored on the Armadillo-X2):
 *     v0 GPU mipmap chains per 100 frames, v1 glGenerateMipmap calls that
 *     took the CPU filter per 100 frames, v2 CPU waits on the GPU outside the
 *     swap per 100 frames, v3 KiB per frame of CPU passes over the GPU
 *     carve-out. With no counters (fb_ok = 0) v0..v3 are all 0xffff.
 */
#ifndef GM_PERF_PAGE_H
#define GM_PERF_PAGE_H

#include <stdint.h>

#include <yakogl_record.h>

#ifdef __cplusplus
extern "C" {
#endif

#define GM_PERF_PAGES 5u

/* page 2's histogram of frame-to-frame times: bucket b holds the intervals
 * of b * GM_PERF_BUCKET_US us up to the next bucket; the last one holds
 * everything from its start on (65.5 ms: 2.5 T is 42.5 ms at 58.76 Hz) */
#define GM_PERF_BUCKET_US 32u
#define GM_PERF_BUCKETS 2048u

/* One scene's totals, as main.cpp gathers them. Times in microseconds. */
struct gm_perf_scene {
	/* page 0: over the scene's frames (each frame's t0 .. t2) */
	uint64_t frames;
	uint64_t frame_us, gl_us, swap_us, show_us;
	/* the frame-to-frame intervals (frames - 1 of them: the last frame has
	 * no next t0) and their sum */
	uint64_t intervals;
	uint64_t interval_us;
	/* page 1: the differences over the scene of the GC7000 OSAL's and
	 * driver's counters */
	uint64_t wait_us, waits, sleeps, busy_us, kicks, submit_us;
	/* page 2: gm_perf_bins' result, T, the slow presents, the tick rate */
	uint32_t bins[3];
	uint32_t period_us;
	uint64_t slow_presents;
	uint32_t ticks_per_sec;
	/* page 3: HI_PROFILE sums over the intervals; bytes = BYTES8 x 8 */
	uint64_t hi_total_cycles, hi_idle_cycles, read_bytes, write_bytes;
	/* page 4: the differences over the scene of gm_gc_fallback.h's counters;
	 * fb_ok 0 when the getter answered an error ("not available") */
	int fb_ok;
	uint64_t mip_gpu, mip_cpu, gpu_waits, carveout_bytes;
};

static inline uint32_t gm_perf_sat(uint64_t v)
{
	return v > 0xffffu ? 0xffffu : (uint32_t)v;
}

/* sum / n, rounded down; 0 for n = 0 */
static inline uint64_t gm_perf_mean(uint64_t sum, uint64_t n)
{
	return n == 0u ? 0u : sum / n;
}

/* Page 2's three bins from the histogram: an interval counts at its
 * bucket's start (t = b * bucket_us, so up to bucket_us early) and goes to
 * bin 0 when t < 1.5 T, bin 1 when t < 2.5 T, bin 2 otherwise. T = 0 (not
 * measured): all three 0. */
static inline void gm_perf_bins(const uint32_t *hist, uint32_t buckets, uint32_t bucket_us,
				uint32_t period_us, uint32_t bins[3])
{
	uint64_t n[3] = {0u, 0u, 0u};

	for (uint32_t b = 0; period_us != 0u && b < buckets; b++) {
		const uint64_t t2 = 2u * (uint64_t)b * bucket_us; /* 2 t */

		n[t2 < 3u * (uint64_t)period_us ? 0 : t2 < 5u * (uint64_t)period_us ? 1 : 2] += hist[b];
	}
	for (int i = 0; i < 3; i++) {
		bins[i] = n[i] > 0xffffffffu ? 0xffffffffu : (uint32_t)n[i];
	}
}

/* The six values of `page`. -1 for a page that is not 0..4. */
static inline int gm_perf_page_values(uint32_t page, const struct gm_perf_scene *s, uint32_t v[6])
{
	const uint64_t f = s->frames, k = s->intervals;
	uint64_t x[6] = {0u, 0u, 0u, 0u, 0u, 0u};

	switch (page) {
	case 0:
		x[0] = f;
		x[1] = gm_perf_mean(s->frame_us, f);
		x[2] = gm_perf_mean(s->gl_us, f);
		x[3] = gm_perf_mean(s->swap_us, f);
		x[4] = gm_perf_mean(s->show_us, f);
		x[5] = gm_perf_mean(s->interval_us, k);
		break;
	case 1:
		x[0] = gm_perf_mean(s->wait_us, f);
		x[1] = gm_perf_mean(s->waits * 100u, f);
		x[2] = gm_perf_mean(s->sleeps * 100u, f);
		x[3] = gm_perf_mean(s->busy_us, f);
		x[4] = gm_perf_mean(s->kicks * 100u, f);
		x[5] = gm_perf_mean(s->submit_us, f);
		break;
	case 2:
		x[0] = s->bins[0];
		x[1] = s->bins[1];
		x[2] = s->bins[2];
		x[3] = s->period_us;
		x[4] = s->slow_presents;
		x[5] = s->ticks_per_sec;
		break;
	case 3:
		x[0] = gm_perf_mean(s->hi_total_cycles / 1000u, k);
		x[1] = gm_perf_mean(s->hi_idle_cycles / 1000u, k);
		x[2] = gm_perf_mean(s->read_bytes / 1024u, k);
		x[3] = gm_perf_mean(s->write_bytes / 1024u, k);
		x[4] = gm_perf_mean(s->hi_total_cycles, s->interval_us); /* cycles per us = MHz */
		break;
	case 4:
		if (!s->fb_ok) {
			x[0] = x[1] = x[2] = x[3] = 0xffffu;
			break;
		}
		x[0] = gm_perf_mean(s->mip_gpu * 100u, f);
		x[1] = gm_perf_mean(s->mip_cpu * 100u, f);
		x[2] = gm_perf_mean(s->gpu_waits * 100u, f);
		x[3] = gm_perf_mean(s->carveout_bytes / 1024u, f);
		break;
	default:
		return -1;
	}
	for (int i = 0; i < 6; i++) {
		v[i] = gm_perf_sat(x[i]);
	}
	return 0;
}

/* The record's four words for `page`: w[0] as board_result_tag stores it
 * (tag = page), w[1..3] the values. -1 for a page that is not 0..4. */
static inline int gm_perf_page_words(uint32_t page, const struct gm_perf_scene *s, uint32_t w[4])
{
	uint32_t v[6];

	if (gm_perf_page_values(page, s, v) != 0) {
		return -1;
	}
	w[0] = YK_RECORD_MAGIC | YK_RECORD_KIND_PERF << 8 | page;
	w[1] = v[1] << 16 | v[0];
	w[2] = v[3] << 16 | v[2];
	w[3] = v[5] << 16 | v[4];
	return 0;
}

#ifdef __cplusplus
}
#endif

#endif /* GM_PERF_PAGE_H */
```

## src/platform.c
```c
/* SPDX-License-Identifier: Apache-2.0 */
/* SPDX-FileCopyrightText: 2026 Signal Slot, Inc. */
/*
 * What glmark2 takes from an operating system and the image gives instead
 * (include/dlfcn.h, include/glmark2_platform.h):
 *
 *   dlopen/dlsym  YakoGL is linked in: the two libraries glmark2 opens
 *                 (gl-state-egl.cpp: libEGL, then libGLESv2) are the image
 *                 itself, and a symbol is what eglGetProcAddress answers.
 *                 Any other library does not exist, as dlopen says for a
 *                 missing file.
 *   data files    the table glmark2_assets.S holds (CMakeLists.txt).
 *   isatty        "not a terminal" for every descriptor (include/unistd.h).
 */
#include <zephyr/kernel.h>
#include <errno.h>
#include <string.h>

#include <EGL/egl.h>

#include "dlfcn.h"
#include "unistd.h" /* include/unistd.h: isatty */
#include "glmark2_platform.h"

/* ---- dlopen / dlsym ------------------------------------------------------ */

static int s_lib; /* the handle: one address for "the image" */
static char s_dlerror[96];
static bool s_dlerror_set;

static bool is_gl_library(const char *name)
{
	/* the names gl-state-egl.cpp tries: libEGL.so[.1], libGLESv2.so[.2] */
	return strncmp(name, "libEGL.so", 9) == 0 || strncmp(name, "libGLESv2.so", 12) == 0;
}

void *dlopen(const char *filename, int flags)
{
	ARG_UNUSED(flags);
	if (filename == NULL || !is_gl_library(filename)) {
		snprintk(s_dlerror, sizeof(s_dlerror), "%s: not in this image",
			 filename ? filename : "(main program)");
		s_dlerror_set = true;
		return NULL;
	}
	return &s_lib;
}

void *dlsym(void *handle, const char *symbol)
{
	if (handle != &s_lib) {
		snprintk(s_dlerror, sizeof(s_dlerror), "dlsym: not a handle of dlopen");
		s_dlerror_set = true;
		return NULL;
	}
	void *f = (void *)eglGetProcAddress(symbol);

	if (f == NULL) {
		/* glad asks for every entry point of every version and extension;
		 * one YakoGL lacks stays NULL, as with a real libGLESv2 */
		snprintk(s_dlerror, sizeof(s_dlerror), "%s: undefined symbol", symbol);
		s_dlerror_set = true;
	}
	return f;
}

int dlclose(void *handle)
{
	return handle == &s_lib ? 0 : -1;
}

char *dlerror(void)
{
	if (!s_dlerror_set) {
		return NULL;
	}
	s_dlerror_set = false;
	return s_dlerror;
}

/* ---- the data files ------------------------------------------------------ */

struct glmark2_asset {
	const char *name;
	const void *data;
	size_t size;
};
/* glmark2_assets.S */
extern const struct glmark2_asset glmark2_asset_table[];
extern const size_t glmark2_asset_table_count;

int glmark2_asset_find(const char *path, const void **data, size_t *size)
{
	for (size_t i = 0; i < glmark2_asset_table_count; i++) {
		if (strcmp(glmark2_asset_table[i].name, path) == 0) {
			*data = glmark2_asset_table[i].data;
			*size = glmark2_asset_table[i].size;
			return 0;
		}
	}
	return -1;
}

size_t glmark2_asset_count(void)
{
	return glmark2_asset_table_count;
}

const char *glmark2_asset_name(size_t i)
{
	return i < glmark2_asset_table_count ? glmark2_asset_table[i].name : "";
}

/* ---- isatty (include/unistd.h) ------------------------------------------- */

int isatty(int fd)
{
	ARG_UNUSED(fd);
	errno = ENOTTY;
	return 0;
}

unsigned int glmark2_num_cpus(void)
{
	return arch_num_cpus();
}
```
